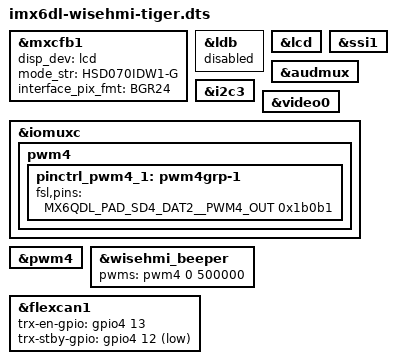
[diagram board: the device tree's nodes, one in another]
#include "imx6dl-wisehmi.dts"

&mxcfb1 {
	disp_dev = "lcd";
	mode_str = "HSD070IDW1-G";
	interface_pix_fmt = "BGR24";
};

&ldb {
	status = "disabled";
};

&lcd {
	status = "okay";
};

&ssi1 {
    status = "okay";
};

&audmux {
    status = "okay";
};

&i2c3 {
    status = "okay";
};

&video0 {
	status = "okay";
};

&iomuxc {
    pwm4 {
        pinctrl_pwm4_1: pwm4grp-1 {
            fsl,pins = <
                MX6QDL_PAD_SD4_DAT2__PWM4_OUT 0x1b0b1
            >;
        };
    };
};

&pwm4 {
    status = "okay";
};

&wisehmi_beeper {
    pwms = <&pwm4 0 500000>;
    status = "okay";
};

&flexcan1 {
    trx-en-gpio = <&gpio4 13 GPIO_ACTIVE_HIGH>;  /* test on rabbit board */
    trx-stby-gpio = <&gpio4 12 GPIO_ACTIVE_LOW>; /* test on rabbit board */
    status = "okay";
};
